# CPU_ITM register map
Vendor: Texas Instruments
Peripheral module from a debugger description file (folder CC26x0R2F).
Registers are 32-bit, read-write, reset 0x0 unless marked. A register's access mark holds for its fields unless they carry their own. Offsets are as the file gives them; lines under a group give offsets from that group; [hi:lo] are bit positions; {n}, {i} and the like mark numbered series; 'fields as' and 'values as' point back to an identical list; <NAME> marks a mode.

## CPU_ITM — Cortex-M's Instrumentation Trace Macrocell (ITM)
{0x0+4i} STIM{i} (i=0..31) — Stimulus Port {i}
  [31:0] STIM{i} — A write to this location causes data to be written into the FIFO if TER.STIMENA{i} is set. Reading from the stimulus port returns the FIFO status in bit [0]: 0 = full, 1 = not full. The polled FIFO interface does not provide an atomic read-modify-write, so it's users responsibility to ensure exclusive read-modify-write if this ITM port is used concurrently by interrupts or other threads.
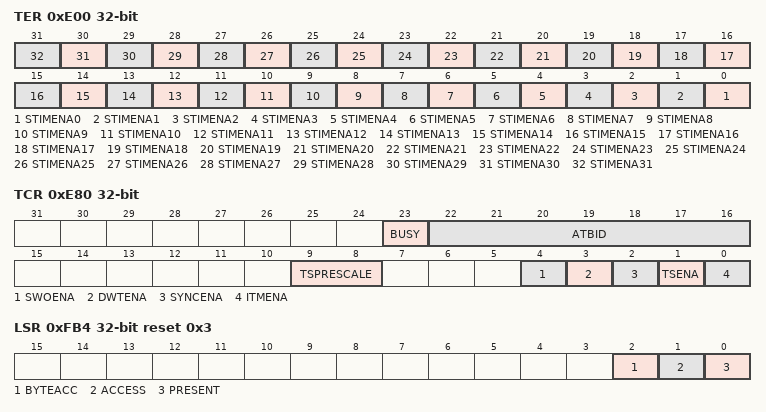
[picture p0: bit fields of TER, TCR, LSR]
0xE00 TER — Trace Enable Use the Trace Enable Register to generate trace data by writing to the corresponding stimulus port. Note: Privileged writes are accepted to this register if TCR.ITMENA is set. User writes are accepted to this register if TCR.ITMENA is set and the appropriate privilege mask is cleared. Privileged access to the stimulus ports enables an RTOS kernel to guarantee instrumentation slots or bandwidth as required.
  [n] STIMENA{n} (n=0..31) — Bit mask to enable tracing on ITM stimulus port {n}.
0xE40 TPR — Trace Privilege This register is used to enable an operating system to control which stimulus ports are accessible by user code. This register can only be used in privileged mode.
  [3:0] PRIVMASK — Bit mask to enable unprivileged (User) access to ITM stimulus ports: Bit [0] enables stimulus ports 0, 1, ..., and 7. Bit [1] enables stimulus ports 8, 9, ..., and 15. Bit [2] enables stimulus ports 16, 17, ..., and 23. Bit [3] enables stimulus ports 24, 25, ..., and 31. 0: User access allowed to stimulus ports 1: Privileged access only to stimulus ports
0xE80 TCR — Trace Control Use this register to configure and control ITM transfers. This register can only be written in privilege mode. DWT is not enabled in the ITM block. However, DWT stimulus entry into the FIFO is controlled by DWTENA. If DWT requires timestamping, the TSENA bit must be set.
  [23] BUSY — Set when ITM events present and being drained.
  [22:16] ATBID — Trace Bus ID for CoreSight system. Optional identifier for multi-source trace stream formatting. If multi-source trace is in use, this field must be written with a non-zero value.
  [9:8] TSPRESCALE — Timestamp prescaler
    3=DIV64 (Divide by 64); 2=DIV16 (Divide by 16); 1=DIV4 (Divide by 4); 0=NOPRESCALING
  [4] SWOENA — Enables asynchronous clocking of the timestamp counter (when TSENA = 1). If TSENA = 0, writing this bit to 1 does not enable asynchronous clocking of the timestamp counter. 0x0: Mode disabled. Timestamp counter uses system clock from the core and counts continuously. 0x1: Timestamp counter uses lineout (data related) clock from TPIU interface. The timestamp counter is held in reset while the output line is idle.
  [3] DWTENA — Enables the DWT stimulus (hardware event packet emission to the TPIU from the DWT)
  [2] SYNCENA — Enables synchronization packet transmission for a synchronous TPIU. CPU_DWT:CTRL.SYNCTAP must be configured for the correct synchronization speed.
  [1] TSENA — Enables differential timestamps. Differential timestamps are emitted when a packet is written to the FIFO with a non-zero timestamp counter, and when the timestamp counter overflows. Timestamps are emitted during idle times after a fixed number of two million cycles. This provides a time reference for packets and inter-packet gaps. If SWOENA (bit [4]) is set, timestamps are triggered by activity on the internal trace bus only. In this case there is no regular timestamp output when the ITM is idle.
  [0] ITMENA — Enables ITM. This is the master enable, and must be set before ITM Stimulus and Trace Enable registers can be written.
0xFB0 LAR wo — Lock Access This register is used to prevent write accesses to the Control Registers: TER, TPR and TCR.
  [31:0] LOCK_ACCESS — A privileged write of 0xC5ACCE55 enables more write access to Control Registers TER, TPR and TCR. An invalid write removes write access.
0xFB4 LSR ro reset 0x3 — Lock Status Use this register to enable write accesses to the Control Register.
  [2] BYTEACC — Reads 0 which means 8-bit lock access is not be implemented.
  [1] ACCESS — Write access to component is blocked. All writes are ignored, reads are permitted.
  [0] PRESENT — Indicates that a lock mechanism exists for this component.
